# STM32MP21_CA35 register map
File version: 0.4
CPU: CM33 r0p1, little endian, MPU, FPU, vendor SysTick, 8 interrupt priority bits
Registers are 32-bit, read-write, reset 0x0 unless marked. A register's access mark holds for its fields unless they carry their own. Offsets are from the block's base; [hi:lo] are bit positions; {n}, {i} and the like mark numbered series.

## SDMMC1 — SDMMC address block description
Base 0x48220000
Same registers: SDMMC2 0x48230000, SDMMC3 0x48240000, SDMMC1_S 0x58220000, SDMMC2_S 0x58230000, SDMMC3_S 0x58240000
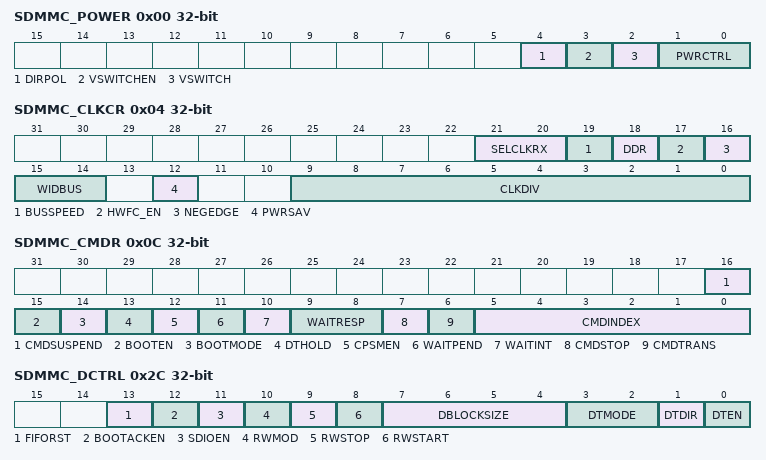
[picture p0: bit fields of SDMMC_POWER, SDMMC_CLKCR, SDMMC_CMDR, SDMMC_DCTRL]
0x00 SDMMC_POWER — SDMMC power control register
  [4] DIRPOL — Data and command direction signals polarity selection This bit can only be written when the SDMMC is in the power-off state (PWRCTRL = 00).
    0=Voltage transceiver IOs driven as output when direction signal is low; 1=Voltage transceiver IOs driven as output when direction signal is high
  [3] VSWITCHEN — Voltage switch procedure enable This bit can only be written by firmware when CPSM is disabled (CPSMEN = 0). This bit is used to stop the SDMMC_CK after the voltage switch command response:
    0=SDMMC_CK clock kept unchanged after successfully received command response; 1=SDMMC_CK clock stopped after successfully received command response
  [2] VSWITCH — Voltage switch sequence start This bit is used to start the timing critical section of the voltage switch sequence:
    0=Voltage switch sequence not started and not active; 1=Voltage switch sequence started or active
  [1:0] PWRCTRL — SDMMC state control bits These bits can only be written when the SDMMC is not in the power-on state (PWRCTRL different 11). These bits are used to define the functional state of the SDMMC signals: When written 00, power-off: the SDMMC is disabled and the clock to the card is stopped, SDMMC_D[7:0], SDMMC_CMD and SDMMC_CK are driven high. Any further write is ignored, PWRCTRL value keeps 11.
    0=After reset, Reset: the SDMMC is disabled and the clock to the Card is stopped, SDMMC_D[7:0], and SDMMC_CMD are HiZ and SDMMC_CK is driven low; 2=Power-cycle, the SDMMC is disabled and the clock to the card is stopped, SDMMC_D[7:0], SDMMC_CMD and SDMMC_CK are driven low; 3=Power-on: the card is clocked, The first 74 SDMMC_CK cycles the SDMMC is still disabled. After the 74 cycles the SDMMC is enabled and the SDMMC_D[7:0], SDMMC_CMD and SDMMC_CK are controlled according the SDMMC operation.
0x04 SDMMC_CLKCR — SDMMC clock control register
  [21:20] SELCLKRX — Receive clock selection These bits can only be written when the CPSM and DPSM are not active (CPSMACT = 0 and DPSMACT = 0)
    0=sdmmc_io_in_ck selected as receive clock; 1=SDMMC_CKIN feedback clock selected as receive clock; 2=sdmmc_fb_ck tuned feedback clock selected as receive clock
  [19] BUSSPEED — Bus speed for selection of SDMMC operating modes This bit can only be written when the CPSM and DPSM are not active (CPSMACT = 0 and DPSMACT = 0)
    0=DS, HS, SDR12, SDR25, Legacy compatible, High speed SDR, High speed DDR bus speed mode selected; 1=SDR50, DDR50, SDR104, HS200 bus speed mode selected
  [18] DDR — Data rate signaling selection This bit can only be written when the CPSM and DPSM are not active (CPSMACT = 0 and DPSMACT = 0) DDR rate must only be selected with 4-bit or 8-bit wide bus mode. (WIDBUS superior 00). DDR = 1 has no effect when WIDBUS = 00 (1-bit wide bus). DDR rate must only be selected with clock division superior1. (CLKDIV superior 0)
    0=SDR Single data rate signaling; 1=DDR double data rate signaling
  [17] HWFC_EN — Hardware flow control enable This bit can only be written when the CPSM and DPSM are not active (CPSMACT = 0 and DPSMACT = 0) When Hardware flow control is enabled, the meaning of the TXFIFOE and RXFIFOF flags change, see SDMMC status register definition in Section 39.10.11.
    0=Hardware flow control is disabled; 1=Hardware flow control is enabled
  [16] NEGEDGE — SDMMC_CK dephasing selection bit for data and command This bit can only be written when the CPSM and DPSM are not active (CPSMACT = 0 and DPSMACT = 0). When clock division = 1 (CLKDIV = 0), this bit has no effect. Data and Command change on SDMMC_CK falling edge. Command and data changed on the sdmmc_ker_ck falling edge succeeding the rising edge of SDMMC_CK. SDMMC_CK edge occurs on sdmmc_ker_ck rising edge. When clock division superior1 (CLKDIV superior 0) and DDR = 1: Command changed on the sdmmc_ker_ck falling edge succeeding the rising edge of SDMMC_CK. Data changed on the sdmmc_ker_ck falling edge succeeding a SDMMC_CK edge. SDMMC_CK edge occurs on sdmmc_ker_ck rising edge. Command and data changed on the same sdmmc_ker_ck rising edge generating the SDMMC_CK falling edge. When clock division superior1 (CLKDIV superior 0) and DDR = 1: Command changed on the same sdmmc_ker_ck rising edge generating the SDMMC_CK falling edge. Data changed on the SDMMC_CK falling edge succeeding a SDMMC_CK edge. SDMMC_CK edge occurs on sdmmc_ker_ck rising edge.
    0=When clock division superior1 (CLKDIV superior 0) and DDR = 0:; 1=When clock division superior1 (CLKDIV superior 0) and DDR = 0:
  [15:14] WIDBUS — Wide bus mode enable bit This bit can only be written when the CPSM and DPSM are not active (CPSMACT = 0 and DPSMACT = 0)
    0=Default 1-bit wide bus mode: SDMMC_D0 used (Does not support DDR); 1=4-bit wide bus mode: SDMMC_D[3:0] used; 2=8-bit wide bus mode: SDMMC_D[7:0] used
  [12] PWRSAV — Power saving configuration bit This bit can only be written when the CPSM and DPSM are not active (CPSMACT = 0 and DPSMACT = 0) For power saving, the SDMMC_CK clock output can be disabled when the bus is idle by setting PWRSAV:
    0=SDMMC_CK clock is always enabled; 1=SDMMC_CK is only enabled when the bus is active
  [9:0] CLKDIV — Clock divide factor This bit can only be written when the CPSM and DPSM are not active (CPSMACT = 0 and DPSMACT = 0). This field defines the divide factor between the input clock (sdmmc_ker_ck) and the output clock (SDMMC_CK): SDMMC_CK frequency = sdmmc_ker_ck / [2 * CLKDIV]. 0x0XX: etc.. 0xXXX: etc..
    0=SDMMC_CK frequency = sdmmc_ker_ck / 1 (Does not support DDR); 1=SDMMC_CK frequency = sdmmc_ker_ck / 2; 2=SDMMC_CK frequency = sdmmc_ker_ck / 4; 128=SDMMC_CK frequency = sdmmc_ker_ck / 256; 0x3FF=SDMMC_CK frequency = sdmmc_ker_ck / 2046
0x08 SDMMC_ARGR — SDMMC argument register
  [31:0] CMDARG — Command argument These bits can only be written by firmware when CPSM is disabled (CPSMEN = 0). Command argument sent to a card as part of a command message. If a command contains an argument, it must be loaded into this register before writing a command to the command register.
0x0C SDMMC_CMDR — SDMMC command register
  [16] CMDSUSPEND — The CPSM treats the command as a Suspend or Resume command and signals interrupt period start/end This bit can only be written by firmware when CPSM is disabled (CPSMEN = 0). CMDSUSPEND = 1 and CMDTRANS = 0 Suspend command, start interrupt period when response bit BS=0. CMDSUSPEND = 1 and CMDTRANS = 1 Resume command with data, end interrupt period when response bit DF=1.
  [15] BOOTEN — Enable boot mode procedure
    0=Boot mode procedure disabled; 1=Boot mode procedure enabled
  [14] BOOTMODE — Select the boot mode procedure to be used This bit can only be written by firmware when CPSM is disabled (CPSMEN = 0)
    0=Normal boot mode procedure selected; 1=Alternative boot mode procedure selected
  [13] DTHOLD — Hold new data block transmission and reception in the DPSM If this bit is set, the DPSM does not move from the Wait_S state to the Send state or from the Wait_R state to the Receive state.
  [12] CPSMEN — Command path state machine (CPSM) enable bit This bit is written 1 by firmware, and cleared by hardware when the CPSM enters the Idle state. If this bit is set, the CPSM is enabled. When DTEN = 1, no command is transfered nor boot procedure is started. CPSMEN is cleared to 0. During Read Wait with SDMMC_CK stopped no command is sent and CPSMEN is kept 0.
  [11] WAITPEND — CPSM waits for end of data transfer (CmdPend internal signal) from DPSM This bit when set, the CPSM waits for the end of data transfer trigger before it starts sending a command. WAITPEND is only taken into account when DTMODE = eMMC stream data transfer, WIDBUS = 1-bit wide bus mode, DPSMACT = 1 and DTDIR = from host to card.
  [10] WAITINT — CPSM waits for interrupt request If this bit is set, the CPSM disables command timeout and waits for an card interrupt request (Response). If this bit is cleared in the CPSM Wait state, it causes the abort of the interrupt mode.
  [9:8] WAITRESP — Wait for response bits This bit can only be written by firmware when CPSM is disabled (CPSMEN = 0). They are used to configure whether the CPSM is to wait for a response, and if yes, which kind of response.
    0=No response, expect CMDSENT flag; 1=Short response, expect CMDREND or CCRCFAIL flag; 2=Short response, expect CMDREND flag (No CRC); 3=Long response, expect CMDREND or CCRCFAIL flag
  [7] CMDSTOP — The CPSM treats the command as a Stop Transmission command and signals abort to the DPSM This bit can only be written by firmware when CPSM is disabled (CPSMEN = 0). If this bit is set, the CPSM issues the abort signal to the DPSM when the command is sent.
  [6] CMDTRANS — The CPSM treats the command as a data transfer command, stops the interrupt period, and signals DataEnable to the DPSM This bit can only be written by firmware when CPSM is disabled (CPSMEN = 0). If this bit is set, the CPSM issues an end of interrupt period and issues DataEnable signal to the DPSM when the command is sent.
  [5:0] CMDINDEX — Command index This bit can only be written by firmware when CPSM is disabled (CPSMEN = 0). The command index is sent to the card as part of a command message.
0x10 SDMMC_RESPCMDR ro — SDMMC command response register
  [5:0] RESPCMD — Response command index Read-only bit field. Contains the command index of the last command response received.
{0x10+4i} SDMMC_RESP{i}R ro (i=1..4) — SDMMC response {i} register
  [31:0] CARDSTATUS — Card status according table below See Table 353.
0x24 SDMMC_DTIMER — SDMMC data timer register
  [31:0] DATATIME — Data and R1b busy timeout period This bit can only be written when the CPSM and DPSM are not active (CPSMACT = 0 and DPSMACT = 0). Data and R1b busy timeout period expressed in card bus clock periods.
0x28 SDMMC_DLENR — SDMMC data length register
  [24:0] DATALENGTH — Data length value This register can only be written by firmware when DPSM is inactive (DPSMACT = 0). Number of data bytes to be transferred. When DDR = 1 DATALENGTH is truncated to a multiple of 2. (The last odd byte is not transfered) When DATALENGTH = 0 no data are transfered, when requested by a CPSMEN and CMDTRANS = 1 also no command is transfered. DTEN and CPSMEN are cleared to 0.
0x2C SDMMC_DCTRL — SDMMC data control register
  [13] FIFORST — FIFO reset, flushes any remaining data This bit can only be written by firmware when IDMAEN= 0 and DPSM is active (DPSMACT = 1). This bit only takes effect when a transfer error or transfer hold occurs.
    0=FIFO not affected; 1=Flush any remaining data and reset the FIFO pointers. This bit is automatically cleared to 0 by hardware when DPSM gets inactive (DPSMACT = 0).
  [12] BOOTACKEN — Enable the reception of the boot acknowledgment This bit can only be written by firmware when DPSM is inactive (DPSMACT = 0).
    0=Boot acknowledgment disabled, not expected to be received; 1=Boot acknowledgment enabled, expected to be received
  [11] SDIOEN — SD I/O interrupt enable functions This bit can only be written by firmware when DPSM is inactive (DPSMACT = 0). If this bit is set, the DPSM enables the SD I/O card specific interrupt operation.
  [10] RWMOD — Read Wait mode This bit can only be written by firmware when DPSM is inactive (DPSMACT = 0).
    0=Read Wait control using SDMMC_D2; 1=Read Wait control stopping SDMMC_CK
  [9] RWSTOP — Read Wait stop This bit is written by firmware and auto cleared by hardware when the DPSM moves from the R_W state to the Wait_R or Idle state.
    0=No Read Wait stop; 1=Enable for Read Wait stop when DPSM is in the R_W state
  [8] RWSTART — Read Wait start If this bit is set, Read Wait operation starts.
  [7:4] DBLOCKSIZE — Data block size This bit can only be written by firmware when DPSM is inactive (DPSMACT = 0). Define the data block length when the block data transfer mode is selected: When DATALENGTH is not a multiple of DBLOCKSIZE, the transfered data is truncated at a multiple of DBLOCKSIZE. (None of the remaining data are transfered.) When DDR = 1, DBLOCKSIZE = 0000 must not be used. (No data are transfered)
    0=Block length = 2supsuperior0/supsuperior = 1 byte; 1=Block length = 2supsuperior1/supsuperior = 2 bytes; 2=Block length = 2supsuperior2 /supsuperior= 4 bytes; 3=Block length = 2supsuperior3/supsuperior = 8 bytes; 4=Block length = 2supsuperior4/supsuperior = 16 bytes; 5=Block length = 2supsuperior5/supsuperior = 32 bytes; 6=Block length = 2supsuperior6/supsuperior = 64 bytes; 7=Block length = 2supsuperior7/supsuperior = 128 bytes; 8=Block length = 2supsuperior8/supsuperior = 256 bytes; 9=Block length = 2supsuperior9/supsuperior = 512 bytes; 10=Block length = 2supsuperior10/supsuperior = 1024 bytes; 11=Block length = 2supsuperior11/supsuperior = 2048 bytes; 12=Block length = 2supsuperior12/supsuperior = 4096 bytes; 13=Block length = 2supsuperior13/supsuperior = 8192 bytes; 14=Block length = 2supsuperior14/supsuperior = 16384 bytes
  [3:2] DTMODE — Data transfer mode selection This bit can only be written by firmware when DPSM is inactive (DPSMACT = 0).
    0=Block data transfer ending on block count; 1=SDIO multibyte data transfer; 2=eMMC Stream data transfer. (WIDBUS must select 1-bit wide bus mode); 3=Block data transfer ending with STOP_TRANSMISSION command (not to be used with DTEN initiated data transfers)
  [1] DTDIR — Data transfer direction selection This bit can only be written by firmware when DPSM is inactive (DPSMACT = 0).
    0=From host to card; 1=From card to host
  [0] DTEN — Data transfer enable bit This bit can only be written by firmware when DPSM is inactive (DPSMACT = 0). This bit is cleared by Hardware when data transfer completes. This bit must only be used to transfer data when no associated data transfer command is used, i.e. must not be used with SD or eMMC cards.
    0=Do not start data transfer without CPSM data transfer command; 1=Start data transfer without CPSM data transfer command
0x30 SDMMC_DCNTR ro — SDMMC data counter register
  [24:0] DATACOUNT — Data count value When read, the number of remaining data bytes to be transferred is returned. Write has no effect.
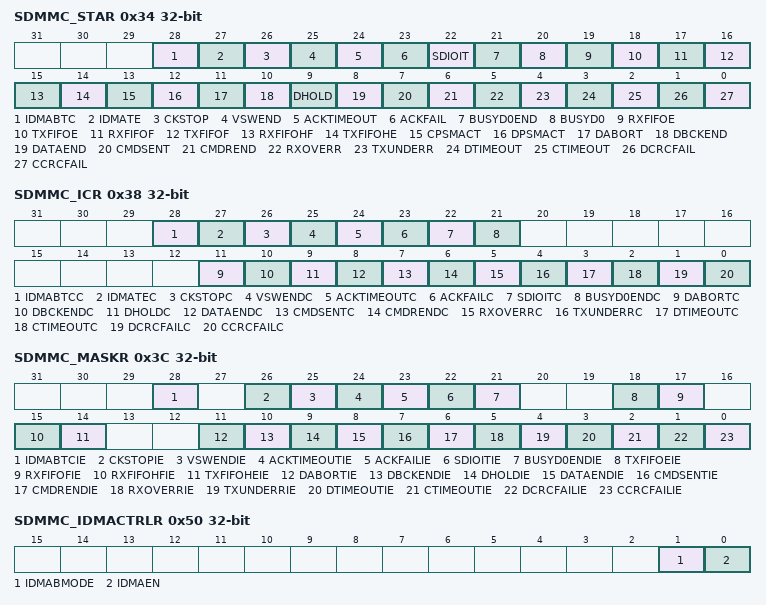
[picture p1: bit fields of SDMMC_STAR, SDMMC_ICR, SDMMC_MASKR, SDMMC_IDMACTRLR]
0x34 SDMMC_STAR ro — SDMMC status register
  [28] IDMABTC — IDMA buffer transfer complete The interrupt flag is cleared by writing corresponding interrupt clear bit in SDMMC_ICR.
  [27] IDMATE — IDMA transfer error The interrupt flag is cleared by writing corresponding interrupt clear bit in SDMMC_ICR.
  [26] CKSTOP — SDMMC_CK stopped in Voltage switch procedure The interrupt flag is cleared by writing corresponding interrupt clear bit in SDMMC_ICR.
  [25] VSWEND — Voltage switch critical timing section completion The interrupt flag is cleared by writing corresponding interrupt clear bit in SDMMC_ICR.
  [24] ACKTIMEOUT — Boot acknowledgment timeout The interrupt flag is cleared by writing corresponding interrupt clear bit in SDMMC_ICR.
  [23] ACKFAIL — Boot acknowledgment received (boot acknowledgment check fail) The interrupt flag is cleared by writing corresponding interrupt clear bit in SDMMC_ICR.
  [22] SDIOIT — SDIO interrupt received The interrupt flag is cleared by writing corresponding interrupt clear bit in SDMMC_ICR.
  [21] BUSYD0END — end of SDMMC_D0 Busy following a CMD response detected This indicates only end of busy following a CMD response. This bit does not signal busy due to data transfer. Interrupt flag is cleared by writing corresponding interrupt clear bit in SDMMC_ICR.
    0=card SDMMC_D0 signal does NOT signal change from busy to not busy; 1=card SDMMC_D0 signal changed from busy to NOT busy
  [20] BUSYD0 — Inverted value of SDMMC_D0 line (Busy), sampled at the end of a CMD response and a second time 2 SDMMC_CK cycles after the CMD response This bit is reset to not busy when the SDMMCD0 line changes from busy to not busy. This bit does not signal busy due to data transfer. This is a hardware status flag only, it does not generate an interrupt.
    0=card signals not busy on SDMMC_D0; 1=card signals busy on SDMMC_D0
  [19] RXFIFOE — Receive FIFO empty This is a hardware status flag only, does not generate an interrupt. This bit is cleared when one FIFO location becomes full.
  [18] TXFIFOE — Transmit FIFO empty This bit is cleared when one FIFO location becomes full.
  [17] RXFIFOF — Receive FIFO full This bit is cleared when one FIFO location becomes empty.
  [16] TXFIFOF — Transmit FIFO full This is a hardware status flag only, does not generate an interrupt. This bit is cleared when one FIFO location becomes empty.
  [15] RXFIFOHF — Receive FIFO half full There are at least half the number of words in the FIFO. This bit is cleared when the FIFO becomes half+1 empty.
  [14] TXFIFOHE — Transmit FIFO half empty At least half the number of words can be written into the FIFO. This bit is cleared when the FIFO becomes half+1 full.
  [13] CPSMACT — Command path state machine active, i.e. not in Idle state This is a hardware status flag only, does not generate an interrupt.
  [12] DPSMACT — Data path state machine active, i.e. not in Idle state This is a hardware status flag only, does not generate an interrupt.
  [11] DABORT — Data transfer aborted by CMD12 Interrupt flag is cleared by writing corresponding interrupt clear bit in SDMMC_ICR.
  [10] DBCKEND — Data block sent/received DBCKEND is set when: - CRC check passed and DPSM moves to the R_W state or - IDMAEN = 0 and transmit data transfer hold and DATACOUNT superior0 and DPSM moves to Wait_S. Interrupt flag is cleared by writing corresponding interrupt clear bit in SDMMC_ICR.
  [9] DHOLD — Data transfer Hold Interrupt flag is cleared by writing corresponding interrupt clear bit in SDMMC_ICR.
  [8] DATAEND — Data transfer ended correctly DATAEND is set if data counter DATACOUNT is zero and no errors occur, and no transmit data transfer hold. Interrupt flag is cleared by writing corresponding interrupt clear bit in SDMMC_ICR.
  [7] CMDSENT — Command sent (no response required) Interrupt flag is cleared by writing corresponding interrupt clear bit in SDMMC_ICR.
  [6] CMDREND — Command response received (CRC check passed, or no CRC) Interrupt flag is cleared by writing corresponding interrupt clear bit in SDMMC_ICR.
  [5] RXOVERR — Received FIFO overrun error (masked by hardware when IDMA is enabled) Interrupt flag is cleared by writing corresponding interrupt clear bit in SDMMC_ICR.
  [4] TXUNDERR — Transmit FIFO underrun error (masked by hardware when IDMA is enabled) Interrupt flag is cleared by writing corresponding interrupt clear bit in SDMMC_ICR.
  [3] DTIMEOUT — Data timeout Interrupt flag is cleared by writing corresponding interrupt clear bit in SDMMC_ICR.
  [2] CTIMEOUT — Command response timeout Interrupt flag is cleared by writing corresponding interrupt clear bit in SDMMC_ICR. The Command Timeout period has a fixed value of 64 SDMMC_CK clock periods.
  [1] DCRCFAIL — Data block sent/received (CRC check failed) Interrupt flag is cleared by writing corresponding interrupt clear bit in SDMMC_ICR.
  [0] CCRCFAIL — Command response received (CRC check failed) Interrupt flag is cleared by writing corresponding interrupt clear bit in SDMMC_ICR.
0x38 SDMMC_ICR — SDMMC interrupt clear register
  [28] IDMABTCC — IDMA buffer transfer complete clear bit Set by software to clear the IDMABTC flag.
    0=IDMABTC not cleared; 1=IDMABTC cleared
  [27] IDMATEC — IDMA transfer error clear bit Set by software to clear the IDMATE flag.
    0=IDMATE not cleared; 1=IDMATE cleared
  [26] CKSTOPC — CKSTOP flag clear bit Set by software to clear the CKSTOP flag.
    0=CKSTOP not cleared; 1=CKSTOP cleared
  [25] VSWENDC — VSWEND flag clear bit Set by software to clear the VSWEND flag.
    0=VSWEND not cleared; 1=VSWEND cleared
  [24] ACKTIMEOUTC — ACKTIMEOUT flag clear bit Set by software to clear the ACKTIMEOUT flag.
    0=ACKTIMEOUT not cleared; 1=ACKTIMEOUT cleared
  [23] ACKFAILC — ACKFAIL flag clear bit Set by software to clear the ACKFAIL flag.
    0=ACKFAIL not cleared; 1=ACKFAIL cleared
  [22] SDIOITC — SDIOIT flag clear bit Set by software to clear the SDIOIT flag.
    0=SDIOIT not cleared; 1=SDIOIT cleared
  [21] BUSYD0ENDC — BUSYD0END flag clear bit Set by software to clear the BUSYD0END flag.
    0=BUSYD0END not cleared; 1=BUSYD0END cleared
  [11] DABORTC — DABORT flag clear bit Set by software to clear the DABORT flag.
    0=DABORT not cleared; 1=DABORT cleared
  [10] DBCKENDC — DBCKEND flag clear bit Set by software to clear the DBCKEND flag.
    0=DBCKEND not cleared; 1=DBCKEND cleared
  [9] DHOLDC — DHOLD flag clear bit Set by software to clear the DHOLD flag.
    0=DHOLD not cleared; 1=DHOLD cleared
  [8] DATAENDC — DATAEND flag clear bit Set by software to clear the DATAEND flag.
    0=DATAEND not cleared; 1=DATAEND cleared
  [7] CMDSENTC — CMDSENT flag clear bit Set by software to clear the CMDSENT flag.
    0=CMDSENT not cleared; 1=CMDSENT cleared
  [6] CMDRENDC — CMDREND flag clear bit Set by software to clear the CMDREND flag.
    0=CMDREND not cleared; 1=CMDREND cleared
  [5] RXOVERRC — RXOVERR flag clear bit Set by software to clear the RXOVERR flag.
    0=RXOVERR not cleared; 1=RXOVERR cleared
  [4] TXUNDERRC — TXUNDERR flag clear bit Set by software to clear TXUNDERR flag.
    0=TXUNDERR not cleared; 1=TXUNDERR cleared
  [3] DTIMEOUTC — DTIMEOUT flag clear bit Set by software to clear the DTIMEOUT flag.
    0=DTIMEOUT not cleared; 1=DTIMEOUT cleared
  [2] CTIMEOUTC — CTIMEOUT flag clear bit Set by software to clear the CTIMEOUT flag.
    0=CTIMEOUT not cleared; 1=CTIMEOUT cleared
  [1] DCRCFAILC — DCRCFAIL flag clear bit Set by software to clear the DCRCFAIL flag.
    0=DCRCFAIL not cleared; 1=DCRCFAIL cleared
  [0] CCRCFAILC — CCRCFAIL flag clear bit Set by software to clear the CCRCFAIL flag.
    0=CCRCFAIL not cleared; 1=CCRCFAIL cleared
0x3C SDMMC_MASKR — SDMMC mask register
  [28] IDMABTCIE — IDMA buffer transfer complete interrupt enable Set and cleared by software to enable/disable the interrupt generated when the IDMA has transferred all data belonging to a memory buffer.
    0=IDMA buffer transfer complete interrupt disabled; 1=IDMA buffer transfer complete interrupt enabled
  [26] CKSTOPIE — Voltage Switch clock stopped interrupt enable Set and cleared by software to enable/disable interrupt caused by Voltage Switch clock stopped.
    0=Voltage Switch clock stopped interrupt disabled; 1=Voltage Switch clock stopped interrupt enabled
  [25] VSWENDIE — Voltage switch critical timing section completion interrupt enable Set and cleared by software to enable/disable the interrupt generated when voltage switch critical timing section completion.
    0=Voltage switch critical timing section completion interrupt disabled; 1=Voltage switch critical timing section completion interrupt enabled
  [24] ACKTIMEOUTIE — Acknowledgment timeout interrupt enable Set and cleared by software to enable/disable interrupt caused by acknowledgment timeout.
    0=Acknowledgment timeout interrupt disabled; 1=Acknowledgment timeout interrupt enabled
  [23] ACKFAILIE — Acknowledgment Fail interrupt enable Set and cleared by software to enable/disable interrupt caused by acknowledgment Fail.
    0=Acknowledgment Fail interrupt disabled; 1=Acknowledgment Fail interrupt enabled
  [22] SDIOITIE — SDIO mode interrupt received interrupt enable Set and cleared by software to enable/disable the interrupt generated when receiving the SDIO mode interrupt.
    0=SDIO Mode interrupt received interrupt disabled; 1=SDIO Mode interrupt received interrupt enabled
  [21] BUSYD0ENDIE — BUSYD0END interrupt enable Set and cleared by software to enable/disable the interrupt generated when SDMMC_D0 signal changes from busy to NOT busy following a CMD response.
    0=BUSYD0END interrupt disabled; 1=BUSYD0END interrupt enabled
  [18] TXFIFOEIE — Tx FIFO empty interrupt enable Set and cleared by software to enable/disable interrupt caused by Tx FIFO empty.
    0=Tx FIFO empty interrupt disabled; 1=Tx FIFO empty interrupt enabled
  [17] RXFIFOFIE — Rx FIFO full interrupt enable Set and cleared by software to enable/disable interrupt caused by Rx FIFO full.
    0=Rx FIFO full interrupt disabled; 1=Rx FIFO full interrupt enabled
  [15] RXFIFOHFIE — Rx FIFO half full interrupt enable Set and cleared by software to enable/disable interrupt caused by Rx FIFO half full.
    0=Rx FIFO half full interrupt disabled; 1=Rx FIFO half full interrupt enabled
  [14] TXFIFOHEIE — Tx FIFO half empty interrupt enable Set and cleared by software to enable/disable interrupt caused by Tx FIFO half empty.
    0=Tx FIFO half empty interrupt disabled; 1=Tx FIFO half empty interrupt enabled
  [11] DABORTIE — Data transfer aborted interrupt enable Set and cleared by software to enable/disable interrupt caused by a data transfer being aborted.
    0=Data transfer abort interrupt disabled; 1=Data transfer abort interrupt enabled
  [10] DBCKENDIE — Data block end interrupt enable Set and cleared by software to enable/disable interrupt caused by data block end.
    0=Data block end interrupt disabled; 1=Data block end interrupt enabled
  [9] DHOLDIE — Data hold interrupt enable Set and cleared by software to enable/disable the interrupt generated when sending new data is hold in the DPSM Wait_S state.
    0=Data hold interrupt disabled; 1=Data hold interrupt enabled
  [8] DATAENDIE — Data end interrupt enable Set and cleared by software to enable/disable interrupt caused by data end.
    0=Data end interrupt disabled; 1=Data end interrupt enabled
  [7] CMDSENTIE — Command sent interrupt enable Set and cleared by software to enable/disable interrupt caused by sending command.
    0=Command sent interrupt disabled; 1=Command sent interrupt enabled
  [6] CMDRENDIE — Command response received interrupt enable Set and cleared by software to enable/disable interrupt caused by receiving command response.
    0=Command response received interrupt disabled; 1=command Response received interrupt enabled
  [5] RXOVERRIE — Rx FIFO overrun error interrupt enable Set and cleared by software to enable/disable interrupt caused by Rx FIFO overrun error.
    0=Rx FIFO overrun error interrupt disabled; 1=Rx FIFO overrun error interrupt enabled
  [4] TXUNDERRIE — Tx FIFO underrun error interrupt enable Set and cleared by software to enable/disable interrupt caused by Tx FIFO underrun error.
    0=Tx FIFO underrun error interrupt disabled; 1=Tx FIFO underrun error interrupt enabled
  [3] DTIMEOUTIE — Data timeout interrupt enable Set and cleared by software to enable/disable interrupt caused by data timeout.
    0=Data timeout interrupt disabled; 1=Data timeout interrupt enabled
  [2] CTIMEOUTIE — Command timeout interrupt enable Set and cleared by software to enable/disable interrupt caused by command timeout.
    0=Command timeout interrupt disabled; 1=Command timeout interrupt enabled
  [1] DCRCFAILIE — Data CRC fail interrupt enable Set and cleared by software to enable/disable interrupt caused by data CRC failure.
    0=Data CRC fail interrupt disabled; 1=Data CRC fail interrupt enabled
  [0] CCRCFAILIE — Command CRC fail interrupt enable Set and cleared by software to enable/disable interrupt caused by command CRC failure.
    0=Command CRC fail interrupt disabled; 1=Command CRC fail interrupt enabled
0x40 SDMMC_ACKTIMER — SDMMC acknowledgment timer register
  [24:0] ACKTIME — Boot acknowledgment timeout period This bit can only be written by firmware when CPSM is disabled (CPSMEN = 0). Boot acknowledgment timeout period expressed in card bus clock periods.
0x44 SDMMC_FIFOTHRR — SDMMC data FIFO threshold register
  [3:0] THR — FIFO threshold This bit can only be written by software when DPSM is inactive (DPSMACT = 0). Define the data FIFO threshold: Others: threshold = 2supsuperior(N-1)/supsuperior bytes, threshold must not be programmed bigger than the FIFO size, 256 words. Note: When THR superior DBLOCKSIZE, blocks may not be transferred.
    0=threshold = 0 byte (no threshold)
0x50 SDMMC_IDMACTRLR — SDMMC DMA control register
  [1] IDMABMODE — Buffer mode selection This bit can only be written by firmware when DPSM is inactive (DPSMACT = 0).
    0=Single buffer mode; 1=Linked list mode
  [0] IDMAEN — IDMA enable This bit can only be written by firmware when DPSM is inactive (DPSMACT = 0).
    0=IDMA disabled; 1=IDMA enabled
0x54 SDMMC_IDMABSIZER — SDMMC IDMA buffer size register
  [16:6] IDMABNDT — Number of bytes per buffer This 11-bit value must be multiplied by 16 to get the size of the buffer in 32-bit words and by 64 to get the size of the buffer in bytes. Example: IDMABNDT = 0x001: buffer size = 16 words = 64 bytes. Example: IDMABNDT = 0x400: buffer size = 16384 words = 64 Kbytes. These bits can only be written by firmware when DPSM is inactive (DPSMACT = 0).
0x58 SDMMC_IDMABASER — SDMMC IDMA buffer base address register
  [31:0] IDMABASE — Buffer memory base address bits [31:2], must be word aligned (bit [1:0] are always 0 and read only) This register can be written by firmware when DPSM is inactive (DPSMACT = 0), and can dynamically be written by firmware when DPSM active (DPSMACT = 1).
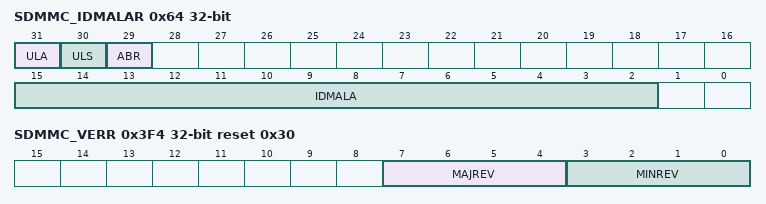
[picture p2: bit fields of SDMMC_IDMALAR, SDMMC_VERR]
0x64 SDMMC_IDMALAR — SDMMC IDMA linked list address register
  [31] ULA — Update SDMMC_IDMALAR from linked list when in linked list mode (SDMMC_IDMACTRLR.IDMABMODE select linked list mode) This bit can only be written by firmware when DPSM is inactive (DPSMACT = 0).
    0=SDMMC_IDMALAR is not to be updated, last linked list item; 1=SDMMC_IDMALAR is to be updated from linked list table
  [30] ULS — Update SDMMC_IDMABSIZE from the next linked list when in linked list mode (SDMMC_IDMACTRLR.IDMABMODE select linked list mode and ULA = 1) This bit can only be written by firmware when DPSM is inactive (DPSMACT = 0).
    0=SDMMC_IDMABSIZER is not to be updated from next linked list table; 1=SDMMC_IDMABSIZER is to be updated from next linked list table
  [29] ABR — Acknowledge linked list buffer ready This bit can only be written by firmware when DPSM is inactive (DPSMACT = 0). This bit is not taken into account when starting the first linked list buffer from the software programmed register information. ABR is only taken into account on subsequent loaded linked list items.
    0=Loaded linked list buffer is not ready (this causes a linked list IDMA transfer error to be generated); 1=Loaded linked list buffer ready acknowledge. Linked list buffer data are transfered by IDMA.
  [15:2] IDMALA — Word aligned linked list item address offset Linked list item offset pointer to the base of the next linked list item structure. Linked list item base address is IDMABA + IDMALA. These bits can only be written by firmware when DPSM is inactive (DPSMACT = 0).
0x68 SDMMC_IDMABAR — SDMMC IDMA linked list memory base register
  [31:2] IDMABA — Word aligned Linked list memory base address Linked list memory base pointer. These bits can only be written by firmware when DPSM is inactive (DPSMACT = 0).
{0x80+4i} SDMMC_FIFOR{i} (i=0..15) — SDMMC data FIFO registers {i}
  [31:0] FIFODATA — Receive and transmit FIFO data This register can only be read or written by firmware when the DPSM is active (DPSMACT = 1). The FIFO data occupies 16 entries of 32-bit words.
0x3F0 SDMMC_HWCFGR1 ro reset 0x4 — SDMMC hardware configuration register 1
  [3:0] FIFOSIZE — SDMMC FIFO size FIFO size = 2supsuperiorN+6/supsuperior bytes, with N in the range 0 to 9 For FIFO size 2supsuperior6/supsuperior bytes, the transfer beat is 8 (32 bytes) For all other FIFO sizes, the transfer beat is 16 (64 bytes)
0x3F4 SDMMC_VERR ro reset 0x30 — SDMMC version register
  [7:4] MAJREV — SDMMC major revision number
  [3:0] MINREV — SDMMC minor revision number
0x3F8 SDMMC_IPIDR ro reset 0x140022 — SDMMC identification register
  [31:0] IP_ID — SDMMC identification
0x3FC SDMMC_SIDR ro reset 0xA3C5DD01 — SDMMC size identification register
  [31:0] SID — SDMMC size identification
